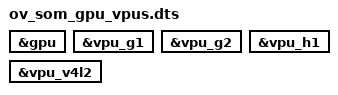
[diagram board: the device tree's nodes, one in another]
/**
 * Portenta-X8 dtb overlay file
 * Arduino 2024
 * Enable several video-related blocks such as gpu and vpus.
 */

/dts-v1/;
/plugin/;

/ {
	fragment@0 {
		target = <&gpu>;
		__overlay__ {
			status = "okay";
		};
	};

	fragment@1 {
		target = <&vpu_g1>;
		__overlay__ {
			status = "okay";
		};
	};

	fragment@2 {
		target = <&vpu_g2>;
		__overlay__ {
			status = "okay";
		};
	};

	fragment@3 {
		target = <&vpu_h1>;
		__overlay__ {
			status = "okay";
		};
	};

	fragment@4 {
		target = <&vpu_v4l2>;
		__overlay__ {
			status = "okay";
		};
	};
};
